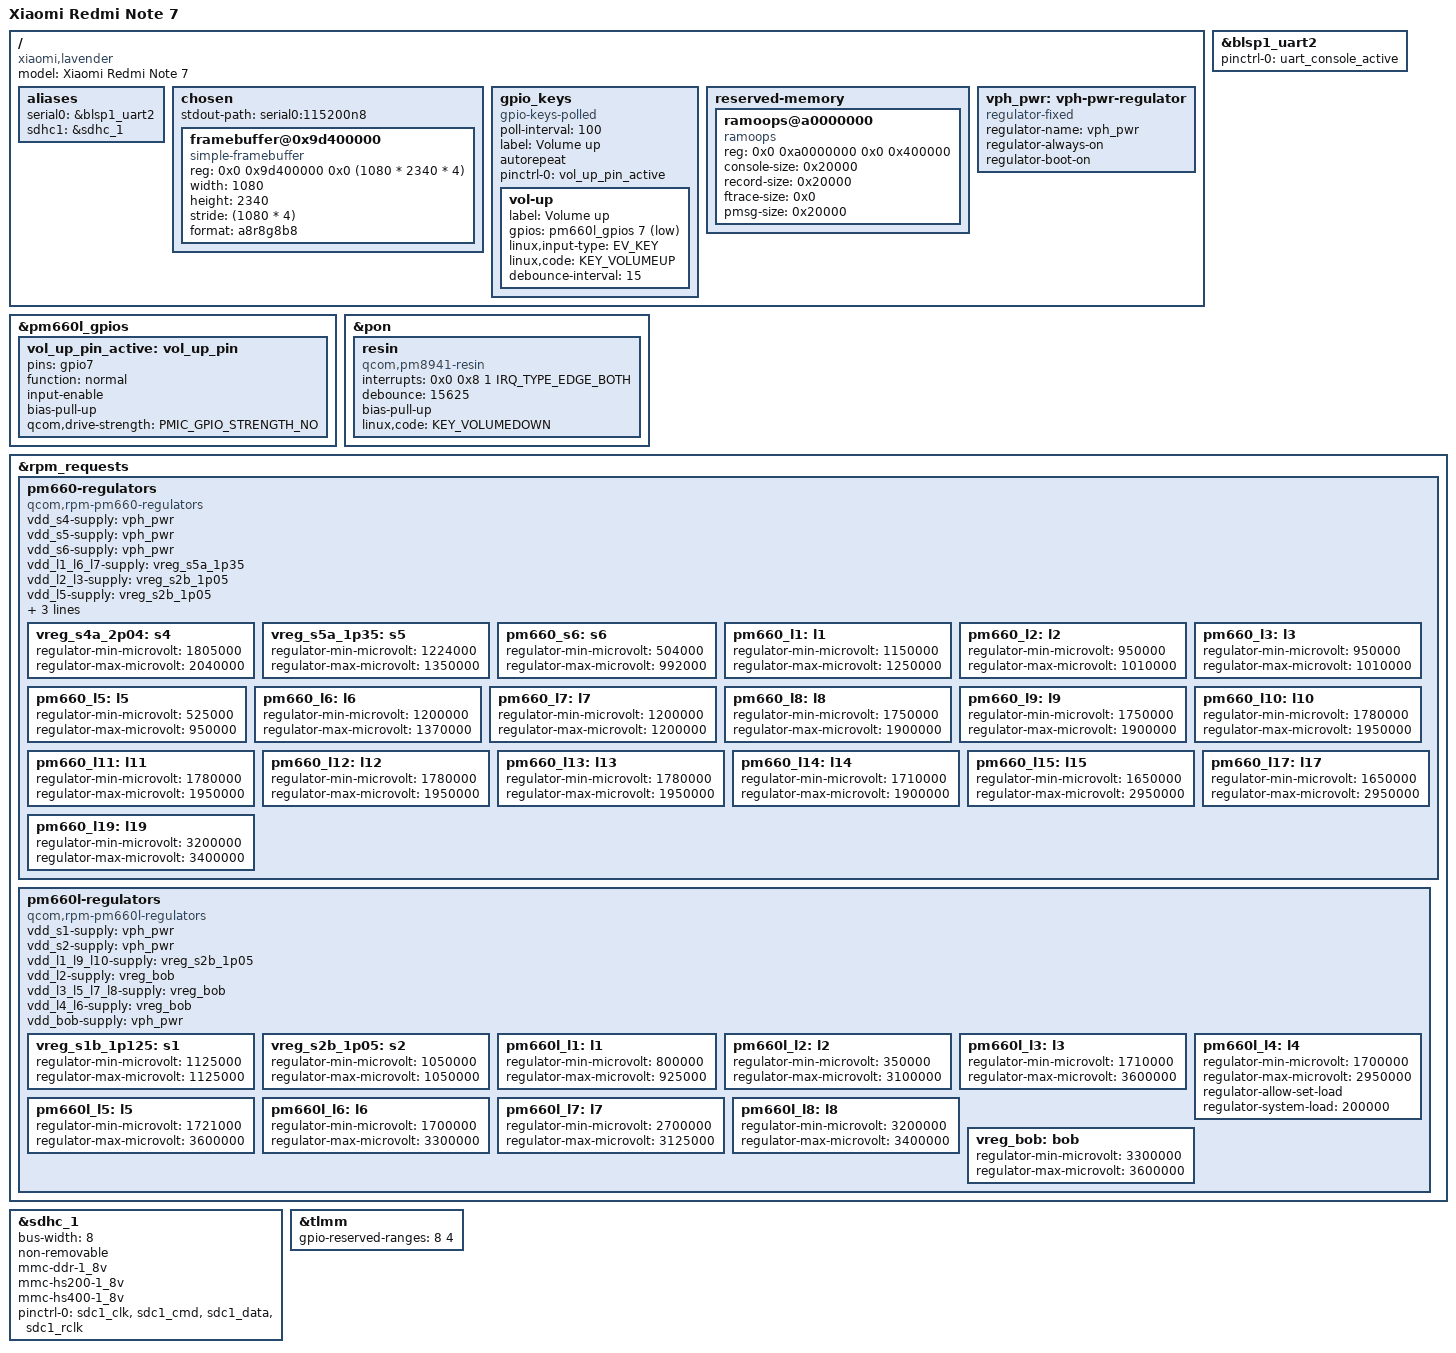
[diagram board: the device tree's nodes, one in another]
// SPDX-License-Identifier: GPL-2.0-only
/*
 * Copyright (c) 2020, Alexey Minnekhanov <alexey.min@gmail.com>
 */

/dts-v1/;

#include <dt-bindings/gpio/gpio.h>
#include <dt-bindings/input/linux-event-codes.h>
#include <dt-bindings/pinctrl/qcom,pmic-gpio.h>
#include "sdm660.dtsi"
#include "pm660.dtsi"
#include "pm660l.dtsi"

/ {
	model = "Xiaomi Redmi Note 7";
	compatible = "xiaomi,lavender", "qcom,sdm660";

	aliases {
		serial0 = &blsp1_uart2;
		sdhc1 = &sdhc_1; /* SDC1 eMMC slot */
	};

	chosen {
		#address-cells = <2>;
		#size-cells = <2>;
		ranges;

		stdout-path = "serial0:115200n8";

		framebuffer@0x9d400000 {
			compatible = "simple-framebuffer";
			reg = <0x0 0x9d400000 0x0 (1080 * 2340 * 4)>;
			width = <1080>;
			height = <2340>;
			stride = <(1080 * 4)>;
			format = "a8r8g8b8";
		};
	};

	gpio_keys {
		/* compatible = "gpio-keys"; does not work */
		compatible = "gpio-keys-polled";
		poll-interval = <100>; /* needed only for gpio-keys-polled */
		label = "Volume up";
		autorepeat;
		pinctrl-names = "default";
		pinctrl-0 = <&vol_up_pin_active>;

		vol-up {
			label = "Volume up";
			gpios = <&pm660l_gpios 7 GPIO_ACTIVE_LOW>;
			linux,input-type = <EV_KEY>;
			linux,code = <KEY_VOLUMEUP>;
			debounce-interval = <15>;
			/* wakeup-source; Note: gpio-keys-polled does not support this */
		};
	};

	reserved-memory {
		#address-cells = <2>;
		#size-cells = <2>;
		ranges;

		ramoops@a0000000 {
			compatible = "ramoops";
			reg = <0x0 0xa0000000 0x0 0x400000>;
			console-size = <0x20000>;
			record-size = <0x20000>;
			ftrace-size = <0x0>;
			pmsg-size = <0x20000>;
		};
	};

	vph_pwr: vph-pwr-regulator {
		compatible = "regulator-fixed";
		regulator-name = "vph_pwr";
		regulator-always-on;
		regulator-boot-on;
	};
};

&blsp1_uart2 {
	status = "okay";
	pinctrl-names = "default";
	pinctrl-0 = <&uart_console_active>;
};

&pm660l_gpios {
	vol_up_pin_active: vol_up_pin {
		pins = "gpio7";
		function = "normal";
		input-enable;
		bias-pull-up;
		qcom,drive-strength = <PMIC_GPIO_STRENGTH_NO>;
	};
};

&pon {
	resin {
		compatible = "qcom,pm8941-resin";
		interrupts = <0x0 0x8 1 IRQ_TYPE_EDGE_BOTH>;
		debounce = <15625>;
		bias-pull-up;
		linux,code = <KEY_VOLUMEDOWN>;
	};
};

&rpm_requests {
	pm660-regulators {
		compatible = "qcom,rpm-pm660-regulators";

		vdd_s4-supply = <&vph_pwr>;
		vdd_s5-supply = <&vph_pwr>;
		vdd_s6-supply = <&vph_pwr>;
		vdd_l1_l6_l7-supply = <&vreg_s5a_1p35>;
		vdd_l2_l3-supply = <&vreg_s2b_1p05>;
		vdd_l5-supply =  <&vreg_s2b_1p05>;
		vdd_l8_l9_l10_l11_l12_l13_l14-supply = <&vreg_s4a_2p04>;
		vdd_l15_l16_l17_l18_l19-supply = <&vreg_bob>;

		vreg_s4a_2p04: s4 {
			regulator-min-microvolt = <1805000>;
			regulator-max-microvolt = <2040000>;
		};
		vreg_s5a_1p35: s5 {
			regulator-min-microvolt = <1224000>;
			regulator-max-microvolt = <1350000>;
		};
		pm660_s6: s6 {
			regulator-min-microvolt = <504000>;
			regulator-max-microvolt = <992000>;
		};
		pm660_l1: l1 {
			regulator-min-microvolt = <1150000>;
			regulator-max-microvolt = <1250000>;
		};
		pm660_l2: l2 {
			regulator-min-microvolt = <950000>;
			regulator-max-microvolt = <1010000>;
		};
		pm660_l3: l3 {
			regulator-min-microvolt = <950000>;
			regulator-max-microvolt = <1010000>;
		};
		pm660_l5: l5 {
			regulator-min-microvolt = <525000>;
			regulator-max-microvolt = <950000>;
		};
		pm660_l6: l6 {
			regulator-min-microvolt = <1200000>;
			regulator-max-microvolt = <1370000>;
		};
		pm660_l7: l7 {
			regulator-min-microvolt = <1200000>;
			regulator-max-microvolt = <1200000>;
		};
		pm660_l8: l8 {
			regulator-min-microvolt = <1750000>;
			regulator-max-microvolt = <1900000>;
			//regulator-boot-on;
			//regulator-allow-set-load;
		};
		pm660_l9: l9 {
			regulator-min-microvolt = <1750000>;
			regulator-max-microvolt = <1900000>;
		};
		pm660_l10: l10 {
			regulator-min-microvolt = <1780000>;
			regulator-max-microvolt = <1950000>;
		};
		pm660_l11: l11 {
			regulator-min-microvolt = <1780000>;
			regulator-max-microvolt = <1950000>;
		};
		pm660_l12: l12 {
			regulator-min-microvolt = <1780000>;
			regulator-max-microvolt = <1950000>;
		};
		pm660_l13: l13 {
			regulator-min-microvolt = <1780000>;
			regulator-max-microvolt = <1950000>;
		};
		pm660_l14: l14 {
			regulator-min-microvolt = <1710000>;
			regulator-max-microvolt = <1900000>;
		};
		pm660_l15: l15 {
			regulator-min-microvolt = <1650000>;
			regulator-max-microvolt = <2950000>;
		};
		pm660_l17: l17 {
			regulator-min-microvolt = <1650000>;
			regulator-max-microvolt = <2950000>;
		};
		pm660_l19: l19 {
			regulator-min-microvolt = <3200000>;
			regulator-max-microvolt = <3400000>;
		};
	};

	pm660l-regulators {
		compatible = "qcom,rpm-pm660l-regulators";

		vdd_s1-supply = <&vph_pwr>;
		vdd_s2-supply = <&vph_pwr>;
		vdd_l1_l9_l10-supply = <&vreg_s2b_1p05>;
		vdd_l2-supply = <&vreg_bob>;
		vdd_l3_l5_l7_l8-supply = <&vreg_bob>;
		vdd_l4_l6-supply = <&vreg_bob>;
		/* downstream has this in dmesg: pm660l_l7: supplied by pm660_l10, WTF */
		vdd_bob-supply = <&vph_pwr>;

		vreg_s1b_1p125: s1 {
			regulator-min-microvolt = <1125000>;
			regulator-max-microvolt = <1125000>;
		};
		vreg_s2b_1p05: s2 {
			regulator-min-microvolt = <1050000>;
			regulator-max-microvolt = <1050000>;
		};
		pm660l_l1: l1 {
			regulator-min-microvolt = <800000>;
			regulator-max-microvolt = <925000>;
		};
		pm660l_l2: l2 {
			regulator-min-microvolt = <350000>;
			regulator-max-microvolt = <3100000>;
		};
		pm660l_l3: l3 {
			regulator-min-microvolt = <1710000>;
			regulator-max-microvolt = <3600000>;
		};
		pm660l_l4: l4 {
			regulator-min-microvolt = <1700000>;
			regulator-max-microvolt = <2950000>;
			/* regulator-boot-on;   - nope, breaks things */
			regulator-allow-set-load;         /* opendata had this */
			regulator-system-load = <200000>; /* opendata had this */
		};
		pm660l_l5: l5 {
			regulator-min-microvolt = <1721000>;
			regulator-max-microvolt = <3600000>;
		};
		pm660l_l6: l6 {
			regulator-min-microvolt = <1700000>;
			regulator-max-microvolt = <3300000>;
		};
		pm660l_l7: l7 {
			regulator-min-microvolt = <2700000>;
			regulator-max-microvolt = <3125000>;
		};
		pm660l_l8: l8 {
			regulator-min-microvolt = <3200000>;
			regulator-max-microvolt = <3400000>;
		};
		vreg_bob: bob {
			regulator-min-microvolt = <3300000>;
			regulator-max-microvolt = <3600000>;
		};
	};
};

&sdhc_1 {
	status = "okay";
	bus-width = <8>;
	non-removable;
	mmc-ddr-1_8v;    /* eMMC high-speed DDR mode (1.8V I/O) is supported. */
	mmc-hs200-1_8v;  /* eMMC HS200 mode (1.8V I/O) is supported. */
	mmc-hs400-1_8v;  /* eMMC HS400 mode (1.8V I/O) is supported. */
	//vmmc-supply = <&pm660l_l4>;  /* Supply for the card power */
	//vqmmc-supply = <&pm660_l8>;  /* Supply for the bus IO line power */
	/* opendata had SDHCI_QUIRK2_BROKEN_HS200 set in .quirks2 member for sdhci-msm driver */
	pinctrl-names = "default";
	pinctrl-0 = <&sdc1_clk &sdc1_cmd &sdc1_data &sdc1_rclk>;
};

&tlmm {
	gpio-reserved-ranges = <8 4>;
};
